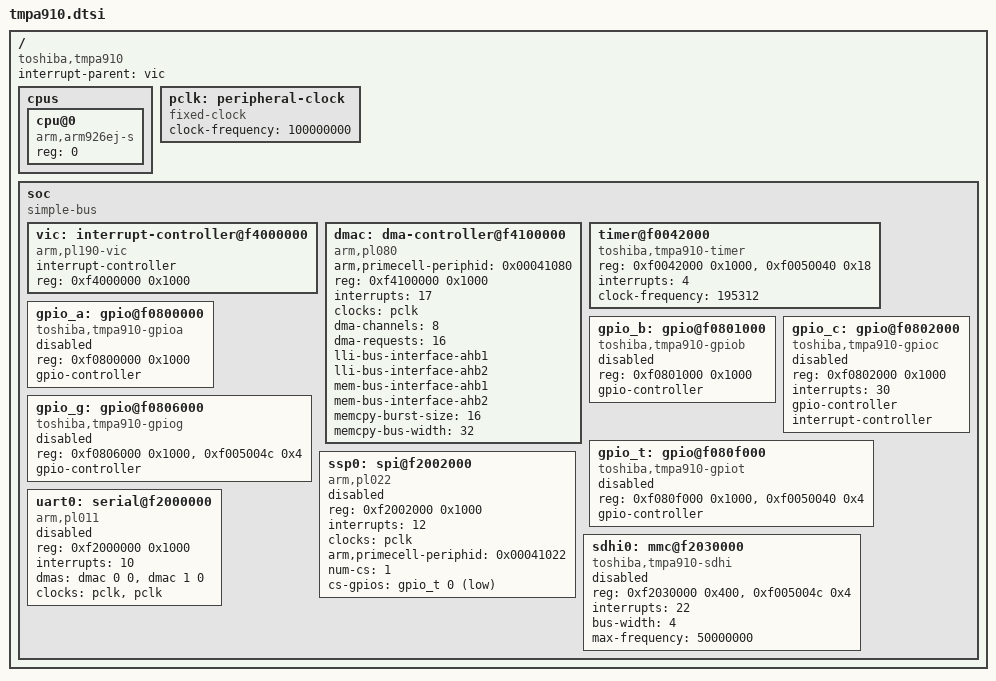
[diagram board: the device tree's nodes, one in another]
// SPDX-License-Identifier: GPL-2.0-only
/*
 * Toshiba TMPA910 device tree description.
 */
#include <dt-bindings/interrupt-controller/irq.h>
#include <dt-bindings/gpio/gpio.h>
/ {
	#address-cells = <1>;
	#size-cells = <1>;
	compatible = "toshiba,tmpa910";
	interrupt-parent = <&vic>;

	cpus {
		#address-cells = <1>;
		#size-cells = <0>;
		cpu@0 {
			compatible = "arm,arm926ej-s";
			device_type = "cpu";
			reg = <0>;
		};
	};

	pclk: peripheral-clock {
		compatible = "fixed-clock";
		#clock-cells = <0>;
		clock-frequency = <100000000>;
	};

	soc {
		compatible = "simple-bus";
		#address-cells = <1>;
		#size-cells = <1>;
		ranges;

		vic: interrupt-controller@f4000000 {
			compatible = "arm,pl190-vic";
			interrupt-controller;
			#interrupt-cells = <1>;
			reg = <0xf4000000 0x1000>;
		};

		/*
		 * TMPA910 DMAC is an ARM PL080-compatible 8-channel engine.
		 * DMA request 0 is UART0 TX and request 1 is UART0 RX.  The
		 * existing amba-pl08x driver supplies IRQ completion handling and
		 * linked-list transfers for the PL011 driver.
		 *
		 */
		dmac: dma-controller@f4100000 {
			compatible = "arm,pl080", "arm,primecell";
			arm,primecell-periphid = <0x00041080>;
			reg = <0xf4100000 0x1000>;
			interrupts = <17>;
			clocks = <&pclk>;
			clock-names = "apb_pclk";
			#dma-cells = <2>;
			dma-channels = <8>;
			dma-requests = <16>;
			lli-bus-interface-ahb1;
			lli-bus-interface-ahb2;
			mem-bus-interface-ahb1;
			mem-bus-interface-ahb2;
			memcpy-burst-size = <16>;
			memcpy-bus-width = <32>;
		};

		timer@f0042000 {
			compatible = "toshiba,tmpa910-timer";
			reg = <0xf0042000 0x1000>, <0xf0050040 0x18>;
			reg-names = "timer", "clock-control";
			interrupts = <4>;
			clock-frequency = <195312>;
		};

		gpio_a: gpio@f0800000 {
			compatible = "toshiba,tmpa910-gpioa";
			reg = <0xf0800000 0x1000>;
			gpio-controller;
			#gpio-cells = <2>;
			status = "disabled";
		};

		gpio_b: gpio@f0801000 {
			compatible = "toshiba,tmpa910-gpiob";
			reg = <0xf0801000 0x1000>;
			gpio-controller;
			#gpio-cells = <2>;
			status = "disabled";
		};

		gpio_c: gpio@f0802000 {
			compatible = "toshiba,tmpa910-gpioc";
			reg = <0xf0802000 0x1000>;
			interrupts = <30>;
			gpio-controller;
			#gpio-cells = <2>;
			interrupt-controller;
			#interrupt-cells = <2>;
			status = "disabled";
		};

		gpio_g: gpio@f0806000 {
			compatible = "toshiba,tmpa910-gpiog";
			reg = <0xf0806000 0x1000>, <0xf005004c 0x4>;
			reg-names = "gpio", "clock-control";
			gpio-controller;
			#gpio-cells = <2>;
			status = "disabled";
		};

		gpio_t: gpio@f080f000 {
			compatible = "toshiba,tmpa910-gpiot";
			reg = <0xf080f000 0x1000>, <0xf0050040 0x4>;
			reg-names = "gpio", "clock-control";
			gpio-controller;
			#gpio-cells = <2>;
			status = "disabled";
		};

		ssp0: spi@f2002000 {
			compatible = "arm,pl022", "arm,primecell";
			reg = <0xf2002000 0x1000>;
			interrupts = <12>;
			clocks = <&pclk>;
			clock-names = "apb_pclk";
			arm,primecell-periphid = <0x00041022>;
			num-cs = <1>;
			cs-gpios = <&gpio_t 0 GPIO_ACTIVE_LOW>;
			#address-cells = <1>;
			#size-cells = <0>;
			status = "disabled";
		};

		uart0: serial@f2000000 {
			compatible = "arm,pl011", "arm,primecell";
			reg = <0xf2000000 0x1000>;
			interrupts = <10>;
			dmas = <&dmac 0 0>, <&dmac 1 0>;
			dma-names = "tx", "rx";
			clocks = <&pclk>, <&pclk>;
			clock-names = "uartclk", "apb_pclk";
			status = "disabled";
		};


		sdhi0: mmc@f2030000 {
			compatible = "toshiba,tmpa910-sdhi";
			reg = <0xf2030000 0x400>,
			      <0xf005004c 0x4>;
			reg-names = "sdhi", "clock-control";
			interrupts = <22>;
			bus-width = <4>;
			max-frequency = <50000000>;
			status = "disabled";
		};
	};
};
